# max32520 register map
Vendor: Maxim-Integrated; Series: ARMCM4; File version: 1.1
CPU: CM4 r2p1, little endian, MPU, FPU, 3 interrupt priority bits
Registers are 32-bit, read-write, reset 0x0 unless marked. A register's access mark holds for its fields unless they carry their own. Offsets are from the block's base; [hi:lo] are bit positions; {n}, {i} and the like mark numbered series.

## ICC0 — Instruction Cache Controller Registers
Base 0x4002A000
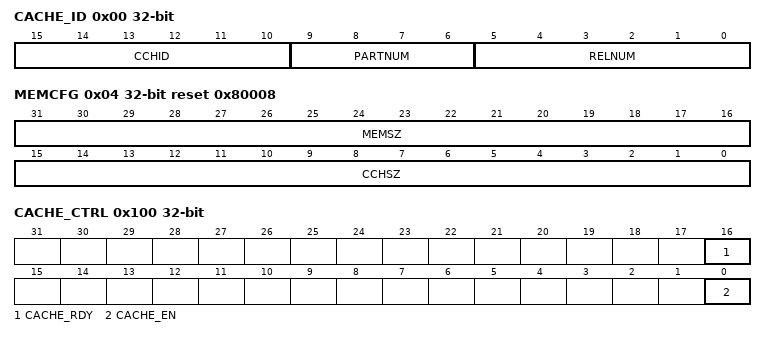
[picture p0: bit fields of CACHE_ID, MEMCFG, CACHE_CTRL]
0x00 CACHE_ID ro
  [15:10] CCHID — Cache ID. This field reflects the value of the C_ID_CACHEID configuration parameter.
  [9:6] PARTNUM — Part Number. This field reflects the value of C_ID_PART_NUMBER configuration parameter.
  [5:0] RELNUM — Release Number. Identifies the RTL release version.
0x04 MEMCFG ro reset 0x80008 — Memory Configuration Register.
  [31:16] MEMSZ — Main Memory Size. Indicates the total size, in units of 128 Kbytes, of code memory accessible to the cache controller.
  [15:0] CCHSZ — Cache Size. Indicates total size in Kbytes of cache.
0x100 CACHE_CTRL — Cache Control and Status Register.
  [16] CACHE_RDY ro — Cache Ready flag. Cleared by hardware when at any time the cache as a whole is invalidated (including a system reset). When this bit is 0, the cache is effectively in bypass mode (instruction fetches will come from main memory or from the line fill buffer). Set by hardware when the invalidate operation is complete and the cache is ready.
    0=notReady; 1=ready
  [0] CACHE_EN — Cache Enable. Controls whether the cache is bypassed or is in use. Changing the state of this bit will cause the instruction cache to be flushed and its contents invalidated.
    0=dis (Cache Bypassed. Instruction data is stored in the line fill buffer but is not written to main cache memory array.); 1=en (Cache Enabled.)
0x700 INVALIDATE — Invalidate All Registers.
  [31:0] IA — Invalidate.

## MCR — Misc Control.
Base 0x40006C00
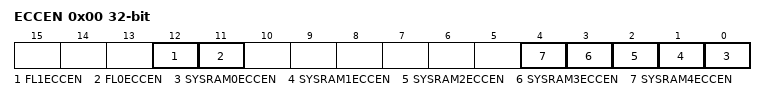
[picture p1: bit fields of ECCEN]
0x00 ECCEN — ECC Enable Register
  [all] fields
    0=dis (disabled.); 1=en (enabled.)
  [12] FL1ECCEN — Flash1 ECC Enable.
  [11] FL0ECCEN — Flash0 ECC Enable.
  [n] SYSRAM{n}ECCEN (n=0..4) — ECC System RAM Enable.

## PWRSEQ — Power Sequencer / Low Power Control Register.
Base 0x40006800
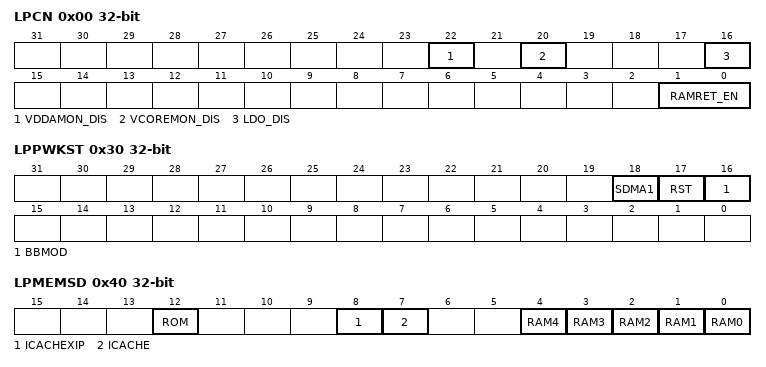
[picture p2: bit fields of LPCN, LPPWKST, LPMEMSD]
0x00 LPCN — Low Power Control Register.
  [22] VDDAMON_DIS — VDDA Monitor Disable. This bit controls the power monitor of the Analog Supply in all operating modes.
    0=en (Enable if Bandgap is ON (default)); 1=dis (Disabled.)
  [20] VCOREMON_DIS — Vcore Monitor Disable. This bit controls the power monitor on the VCore supply in all operating modes.
    0=en (Enable if Bandgap is ON (default)); 1=dis (Disabled.)
  [16] LDO_DIS — LDO Disabled
  [1:0] RAMRET_EN — System RAM retention in BACKUP mode. These two bits are used in conjuction with RREGEN bit.
0x04 LPWKST0 — Low Power I/O Wakeup Status Register 0. This register indicates the low power wakeup status for GPIO0.
  [15:0] ST — Wakeup IRQ flags (write ones to clear). One or more of these bits will be set when the corresponding dedicated GPIO pin (s) transition (s) from low to high or high to low. If GPIO wakeup source is selected, using PM.GPIOWKEN register, and the corresponding bit is also selected in LPWKEN register, an interrupt will be gnerated to wake up the CPU from a low power mode.
0x08 LPWKEN0 — Low Power I/O Wakeup Enable Register 0. This register enables low power wakeup functionality for GPIO0.
  [15:0] EN — Enable wakeup. These bits allow wakeup from the corresponding GPIO pin (s) on transition (s) from low to high or high to low when PM.GPIOWKEN is set. Wakeup status is indicated in PPWKST register.
0x0C LPWKST1 — Low Power I/O Wakeup Status Register 1. This register indicates the low power wakeup status for GPIO1.
  [10:0] ST — Wakeup IRQ flags (write ones to clear). One or more of these bits will be set when the corresponding dedicated GPIO pin (s) transition (s) from low to high or high to low. If GPIO wakeup source is selected, using PM.GPIOWKEN register, and the corresponding bit is also selected in LPWKEN register, an interrupt will be gnerated to wake up the CPU from a low power mode.
0x10 LPWKEN1 — Low Power I/O Wakeup Enable Register 1. This register enables low power wakeup functionality for GPIO1.
  [10:0] EN — Enable wakeup. These bits allow wakeup from the corresponding GPIO pin (s) on transition (s) from low to high or high to low when PM.GPIOWKEN is set. Wakeup status is indicated in PPWKST register.
0x30 LPPWKST — Low Power Peripheral Wakeup Status Register.
  [18] SDMA1 — Smart DMA (1) Detect Wakeup Flag (write one to clear). This bit will be set when the SDMA IRQ transitions from low to high or high to low
  [17] RST — Reset Detect Wakeup Flag (write one to clear). This bit will be set when the external reset causes wakeup
  [16] BBMOD — Battery Back Wakeup Flag (write one to clear). This bit will be set when exiting Battery Backup Mode.
0x40 LPMEMSD — Low Power Memory Shutdown Control.
  [all] fields
    0=Normal Operating Mode; 1=Shutdown Mode
  [12] ROM — ROM Shut Down.
  [8] ICACHEXIP — XiP Instruction Cache RAM Shut Down.
  [7] ICACHE — Instruction Cache RAM Shut Down.
  [n] RAM{n} (n=0..4) — System RAM block {n} Shut Down.
0x48 GP0 — Back Up General Purpose Register 0
0x4C GP1 — Back Up General Purpose Register 1
